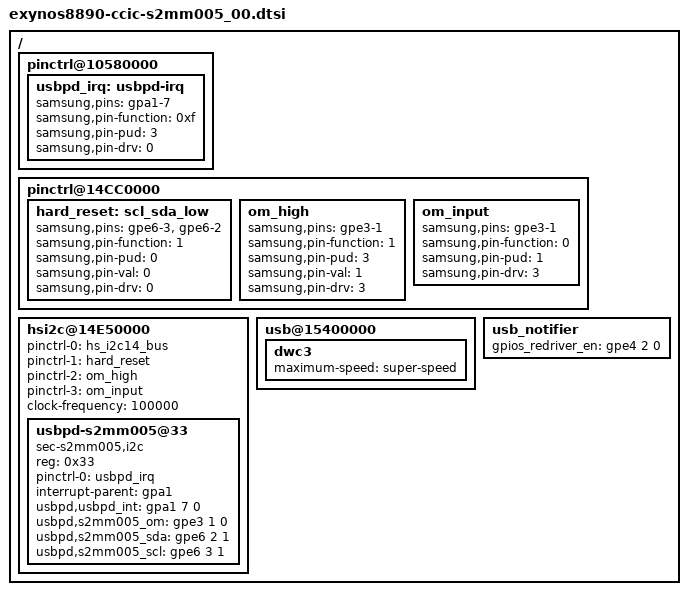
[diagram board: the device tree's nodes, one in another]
/*
 * SAMSUNG Hero Type C S2MM005 CCIC Device Tree Source
 *
 * Copyright (c) 2015 Samsung Electronics Co., Ltd.
 *		http://www.samsung.com
 *
 * This program is free software; you can redistribute it and/or modify
 * it under the terms of the GNU General Public License version 2 as
 * published by the Free Software Foundation.
*/

/ {
	pinctrl@10580000 {
		usbpd_irq: usbpd-irq {
			samsung,pins = "gpa1-7";
			samsung,pin-function = <0xf>;
			samsung,pin-pud = <3>;
			samsung,pin-drv = <0>;
		};
	};

	pinctrl@14CC0000 {
		hard_reset: scl_sda_low {
			samsung,pins = "gpe6-3", "gpe6-2";
			samsung,pin-function = <1>;
			samsung,pin-pud = <0>;
			samsung,pin-val = <0>;
			samsung,pin-drv = <0>;
		};
		om_high: om_high {
			samsung,pins = "gpe3-1";
			samsung,pin-function = <1>;
			samsung,pin-pud = <3>;
			samsung,pin-val = <1>;
			samsung,pin-drv = <3>;
		};
		om_input: om_input {
			samsung,pins = "gpe3-1";
			samsung,pin-function = <0>;
			samsung,pin-pud = <1>;
			samsung,pin-drv = <3>;
		};
	};

	hsi2c@14E50000 {
		status = "okay";
		pinctrl-names = "default","hard_reset","om_high","om_input";
		pinctrl-0 = <&hs_i2c14_bus>;
		pinctrl-1 = <&hard_reset>;
		pinctrl-2 = <&om_high>;
		pinctrl-3 = <&om_input>;
		clock-frequency = <100000>;
/*
		samsung,hs-mode;
		clock-frequency = <3000000>;
        */
		usbpd-s2mm005@33 {
			compatible = "sec-s2mm005,i2c";
			reg = <0x33>;
			pinctrl-names = "default";
			pinctrl-0 = <&usbpd_irq>;
			interrupt-parent = <&gpa1>;
			usbpd,usbpd_int = <&gpa1 7 0>;
			/*usbpd,redriver_en = <&gpe4 2 0>;*/
			usbpd,s2mm005_om = <&gpe3 1 0>;
			usbpd,s2mm005_sda = <&gpe6 2 1>;
			usbpd,s2mm005_scl = <&gpe6 3 1>;
		};
	};

	usb@15400000 {
		dwc3 {
			maximum-speed = "super-speed";
		};
	};

	usb_notifier {
		gpios_redriver_en = <&gpe4 2 0>;
	};
};
